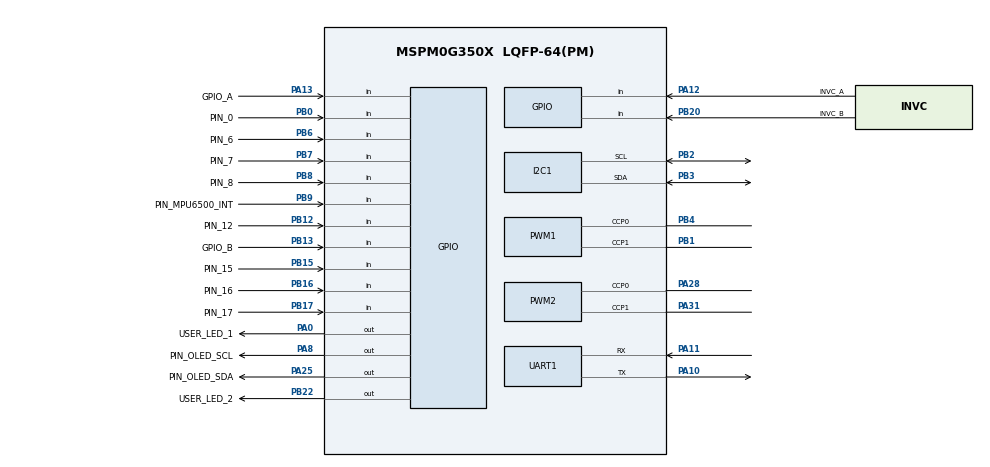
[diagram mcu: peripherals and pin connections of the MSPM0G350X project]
/**
 * @cliArgs --device "MSPM0G350X" --part "Default" --package "LQFP-64(PM)" --product "mspm0_sdk@2.05.00.05"
 * @versions {"tool":"1.24.0+4110"}
 */

/**
 * Import the modules used in this configuration.
 */
const GPIO   = scripting.addModule("/ti/driverlib/GPIO", {}, false);
const GPIO1  = GPIO.addInstance();
const GPIO2  = GPIO.addInstance();
const GPIO3  = GPIO.addInstance();
const GPIO4  = GPIO.addInstance();
const GPIO5  = GPIO.addInstance();
const GPIO6  = GPIO.addInstance();
const GPIO7  = GPIO.addInstance();
const GPIO8  = GPIO.addInstance();
const I2C    = scripting.addModule("/ti/driverlib/I2C", {}, false);
const I2C1   = I2C.addInstance();
const PWM    = scripting.addModule("/ti/driverlib/PWM", {}, false);
const PWM1   = PWM.addInstance();
const PWM2   = PWM.addInstance();
const SYSCTL = scripting.addModule("/ti/driverlib/SYSCTL");
const TIMER  = scripting.addModule("/ti/driverlib/TIMER", {}, false);
const TIMER1 = TIMER.addInstance();
const UART   = scripting.addModule("/ti/driverlib/UART", {}, false);
const UART1  = UART.addInstance();

/**
 * Write custom configuration values to the imported modules.
 */
const divider7       = system.clockTree["PLL_PDIV"];
divider7.divideValue = 2;

const divider9       = system.clockTree["UDIV"];
divider9.divideValue = 2;

const multiplier2         = system.clockTree["PLL_QDIV"];
multiplier2.multiplyValue = 5;

const mux8       = system.clockTree["HSCLKMUX"];
mux8.inputSelect = "HSCLKMUX_SYSPLL2X";

GPIO1.$name                               = "GPIO_MPU6500";
GPIO1.associatedPins[0].$name             = "PIN_MPU6500_INT";
GPIO1.associatedPins[0].direction         = "INPUT";
GPIO1.associatedPins[0].polarity          = "RISE";
GPIO1.associatedPins[0].interruptPriority = "3";
GPIO1.associatedPins[0].interruptEn       = true;
GPIO1.associatedPins[0].pin.$assign       = "PB9";

const Board = scripting.addModule("/ti/driverlib/Board", {}, false);

GPIO2.$name                               = "GPIO_EncoderA";
GPIO2.associatedPins.create(2);
GPIO2.associatedPins[0].$name             = "INVC_A";
GPIO2.associatedPins[0].direction         = "INPUT";
GPIO2.associatedPins[0].interruptEn       = true;
GPIO2.associatedPins[0].polarity          = "FALL";
GPIO2.associatedPins[0].internalResistor  = "PULL_DOWN";
GPIO2.associatedPins[0].assignedPort      = "PORTA";
GPIO2.associatedPins[0].assignedPin       = "12";
GPIO2.associatedPins[0].interruptPriority = "2";
GPIO2.associatedPins[0].pin.$assign       = "PA12";
GPIO2.associatedPins[1].$name             = "GPIO_A";
GPIO2.associatedPins[1].direction         = "INPUT";
GPIO2.associatedPins[1].assignedPin       = "13";
GPIO2.associatedPins[1].internalResistor  = "PULL_DOWN";
GPIO2.associatedPins[1].assignedPort      = "PORTA";
GPIO2.associatedPins[1].pin.$assign       = "PA13";

GPIO3.$name                               = "GPIO_EncoderB";
GPIO3.associatedPins.create(2);
GPIO3.associatedPins[0].$name             = "INVC_B";
GPIO3.associatedPins[0].direction         = "INPUT";
GPIO3.associatedPins[0].internalResistor  = "PULL_DOWN";
GPIO3.associatedPins[0].interruptEn       = true;
GPIO3.associatedPins[0].polarity          = "FALL";
GPIO3.associatedPins[0].assignedPort      = "PORTB";
GPIO3.associatedPins[0].assignedPin       = "20";
GPIO3.associatedPins[0].interruptPriority = "2";
GPIO3.associatedPins[0].pin.$assign       = "PB20";
GPIO3.associatedPins[1].$name             = "GPIO_B";
GPIO3.associatedPins[1].direction         = "INPUT";
GPIO3.associatedPins[1].assignedPin       = "13";
GPIO3.associatedPins[1].internalResistor  = "PULL_DOWN";
GPIO3.associatedPins[1].assignedPort      = "PORTB";
GPIO3.associatedPins[1].pin.$assign       = "PB13";

GPIO4.$name                          = "GPIO_LEDS";
GPIO4.associatedPins[0].$name        = "USER_LED_1";
GPIO4.associatedPins[0].assignedPort = "PORTA";
GPIO4.associatedPins[0].assignedPin  = "0";
GPIO4.associatedPins[0].pin.$assign  = "PA0";

GPIO5.$name                               = "GPIO_BUTTON_B";
GPIO5.associatedPins[0].direction         = "INPUT";
GPIO5.associatedPins[0].internalResistor  = "PULL_UP";
GPIO5.associatedPins[0].$name             = "USER_BUTTON_1";
GPIO5.associatedPins[0].assignedPort      = "PORTB";
GPIO5.associatedPins[0].assignedPin       = "21";
GPIO5.associatedPins[0].interruptPriority = "3";
GPIO5.associatedPins[0].polarity          = "RISE_FALL";

GPIO6.$name                          = "GPIO_RGB";
GPIO6.associatedPins[0].$name        = "USER_LED_2";
GPIO6.associatedPins[0].assignedPort = "PORTB";
GPIO6.associatedPins[0].assignedPin  = "22";
GPIO6.associatedPins[0].pin.$assign  = "PB22";

GPIO7.$name                         = "IR_DH";
GPIO7.associatedPins.create(8);
GPIO7.associatedPins[0].direction   = "INPUT";
GPIO7.associatedPins[0].$name       = "PIN_16";
GPIO7.associatedPins[0].pin.$assign = "PB16";
GPIO7.associatedPins[1].direction   = "INPUT";
GPIO7.associatedPins[1].$name       = "PIN_0";
GPIO7.associatedPins[1].pin.$assign = "PB0";
GPIO7.associatedPins[2].direction   = "INPUT";
GPIO7.associatedPins[2].$name       = "PIN_6";
GPIO7.associatedPins[2].pin.$assign = "PB6";
GPIO7.associatedPins[3].direction   = "INPUT";
GPIO7.associatedPins[3].$name       = "PIN_7";
GPIO7.associatedPins[3].pin.$assign = "PB7";
GPIO7.associatedPins[4].direction   = "INPUT";
GPIO7.associatedPins[4].$name       = "PIN_8";
GPIO7.associatedPins[4].pin.$assign = "PB8";
GPIO7.associatedPins[5].$name       = "PIN_15";
GPIO7.associatedPins[5].direction   = "INPUT";
GPIO7.associatedPins[5].pin.$assign = "PB15";
GPIO7.associatedPins[6].$name       = "PIN_17";
GPIO7.associatedPins[6].direction   = "INPUT";
GPIO7.associatedPins[6].pin.$assign = "PB17";
GPIO7.associatedPins[7].$name       = "PIN_12";
GPIO7.associatedPins[7].direction   = "INPUT";
GPIO7.associatedPins[7].pin.$assign = "PB12";

GPIO8.$name                         = "GPIO_OLED";
GPIO8.associatedPins.create(2);
GPIO8.associatedPins[0].$name       = "PIN_OLED_SCL";
GPIO8.associatedPins[0].pin.$assign = "PA8";
GPIO8.associatedPins[1].$name       = "PIN_OLED_SDA";
GPIO8.associatedPins[1].pin.$assign = "PA25";

I2C1.$name                             = "I2C_MPU6500";
I2C1.basicEnableController             = true;
I2C1.basicControllerStandardBusSpeed   = "FastPlus";
I2C1.peripheral.$assign                = "I2C1";
I2C1.peripheral.sdaPin.$assign         = "PB3";
I2C1.peripheral.sclPin.$assign         = "PB2";
I2C1.sdaPinConfig.$name                = "ti_driverlib_gpio_GPIOPinGeneric0";
I2C1.sdaPinConfig.hideOutputInversion  = scripting.forceWrite(false);
I2C1.sdaPinConfig.onlyInternalResistor = scripting.forceWrite(false);
I2C1.sdaPinConfig.passedPeripheralType = scripting.forceWrite("Digital");
I2C1.sclPinConfig.$name                = "ti_driverlib_gpio_GPIOPinGeneric1";
I2C1.sclPinConfig.hideOutputInversion  = scripting.forceWrite(false);
I2C1.sclPinConfig.onlyInternalResistor = scripting.forceWrite(false);
I2C1.sclPinConfig.passedPeripheralType = scripting.forceWrite("Digital");

PWM1.$name                              = "PWM_MOTORA";
PWM1.pwmMode                            = "EDGE_ALIGN_UP";
PWM1.clockDivider                       = 2;
PWM1.timerCount                         = 40000;
PWM1.peripheral.$assign                 = "TIMA1";
PWM1.peripheral.ccp0Pin.$assign         = "PB4";
PWM1.peripheral.ccp1Pin.$assign         = "PB1";
PWM1.PWM_CHANNEL_0.$name                = "ti_driverlib_pwm_PWMTimerCC0";
PWM1.PWM_CHANNEL_1.$name                = "ti_driverlib_pwm_PWMTimerCC1";
PWM1.ccp0PinConfig.$name                = "ti_driverlib_gpio_GPIOPinGeneric2";
PWM1.ccp0PinConfig.direction            = scripting.forceWrite("OUTPUT");
PWM1.ccp0PinConfig.hideOutputInversion  = scripting.forceWrite(false);
PWM1.ccp0PinConfig.onlyInternalResistor = scripting.forceWrite(false);
PWM1.ccp0PinConfig.passedPeripheralType = scripting.forceWrite("Digital");
PWM1.ccp1PinConfig.$name                = "ti_driverlib_gpio_GPIOPinGeneric3";
PWM1.ccp1PinConfig.direction            = scripting.forceWrite("OUTPUT");
PWM1.ccp1PinConfig.hideOutputInversion  = scripting.forceWrite(false);
PWM1.ccp1PinConfig.onlyInternalResistor = scripting.forceWrite(false);
PWM1.ccp1PinConfig.passedPeripheralType = scripting.forceWrite("Digital");

PWM2.$name                              = "PWM_MOTORB";
PWM2.clockDivider                       = 2;
PWM2.timerCount                         = 40000;
PWM2.pwmMode                            = "EDGE_ALIGN_UP";
PWM2.peripheral.$assign                 = "TIMG7";
PWM2.peripheral.ccp0Pin.$assign         = "PA28";
PWM2.peripheral.ccp1Pin.$assign         = "PA31";
PWM2.PWM_CHANNEL_0.$name                = "ti_driverlib_pwm_PWMTimerCC2";
PWM2.PWM_CHANNEL_1.$name                = "ti_driverlib_pwm_PWMTimerCC3";
PWM2.ccp0PinConfig.$name                = "ti_driverlib_gpio_GPIOPinGeneric4";
PWM2.ccp0PinConfig.direction            = scripting.forceWrite("OUTPUT");
PWM2.ccp0PinConfig.hideOutputInversion  = scripting.forceWrite(false);
PWM2.ccp0PinConfig.onlyInternalResistor = scripting.forceWrite(false);
PWM2.ccp0PinConfig.passedPeripheralType = scripting.forceWrite("Digital");
PWM2.ccp1PinConfig.$name                = "ti_driverlib_gpio_GPIOPinGeneric5";
PWM2.ccp1PinConfig.direction            = scripting.forceWrite("OUTPUT");
PWM2.ccp1PinConfig.hideOutputInversion  = scripting.forceWrite(false);
PWM2.ccp1PinConfig.onlyInternalResistor = scripting.forceWrite(false);
PWM2.ccp1PinConfig.passedPeripheralType = scripting.forceWrite("Digital");

SYSCTL.forceDefaultClkConfig = true;
SYSCTL.clockTreeEn           = true;
scripting.suppress("For best practices when the CPUCLK is running at 32MHz and above, clear the flash status bit using DL_FlashCTL_executeClearStatus\\(\\) before executing any flash operation\\. Otherwise there may be false positives\\.", SYSCTL);

TIMER1.$name              = "TIMER_0";
TIMER1.timerMode          = "PERIODIC";
TIMER1.timerClkDiv        = 8;
TIMER1.interrupts         = ["ZERO"];
TIMER1.timerPeriod        = "10 ms";
TIMER1.timerClkPrescale   = 10;
TIMER1.interruptPriority  = "2";
TIMER1.peripheral.$assign = "TIMA0";

UART1.$name                    = "UART_0";
UART1.enabledInterrupts        = ["RX"];
UART1.interruptPriority        = "2";
UART1.peripheral.$assign       = "UART0";
UART1.peripheral.rxPin.$assign = "PA11";
UART1.peripheral.txPin.$assign = "PA10";
UART1.txPinConfig.$name        = "ti_driverlib_gpio_GPIOPinGeneric6";
UART1.rxPinConfig.$name        = "ti_driverlib_gpio_GPIOPinGeneric7";

/**
 * Pinmux solution for unlocked pins/peripherals. This ensures that minor changes to the automatic solver in a future
 * version of the tool will not impact the pinmux you originally saw.  These lines can be completely deleted in order to
 * re-solve from scratch.
 */
Board.peripheral.$suggestSolution            = "DEBUGSS";
Board.peripheral.swclkPin.$suggestSolution   = "PA20";
Board.peripheral.swdioPin.$suggestSolution   = "PA19";
GPIO5.associatedPins[0].pin.$suggestSolution = "PB21";
